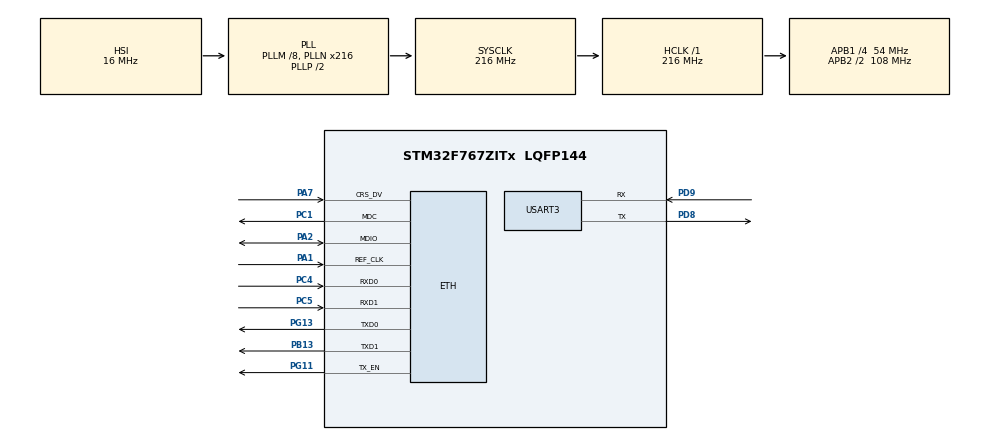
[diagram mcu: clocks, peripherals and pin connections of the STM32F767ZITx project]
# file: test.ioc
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CORTEX_M7.AccessPermission-Cortex_Memory_Protection_Unit_Region1_Settings=MPU_REGION_FULL_ACCESS
CORTEX_M7.AccessPermission-Cortex_Memory_Protection_Unit_Region2_Settings=MPU_REGION_FULL_ACCESS
CORTEX_M7.BaseAddress-Cortex_Memory_Protection_Unit_Region0_Settings=0x70000000
CORTEX_M7.BaseAddress-Cortex_Memory_Protection_Unit_Region1_Settings=0x70000000
CORTEX_M7.BaseAddress-Cortex_Memory_Protection_Unit_Region2_Settings=0x70000000
CORTEX_M7.CPU_DCache=Enabled
CORTEX_M7.CPU_ICache=Enabled
CORTEX_M7.DisableExec-Cortex_Memory_Protection_Unit_Region0_Settings=MPU_INSTRUCTION_ACCESS_DISABLE
CORTEX_M7.DisableExec-Cortex_Memory_Protection_Unit_Region1_Settings=MPU_INSTRUCTION_ACCESS_DISABLE
CORTEX_M7.Enable-Cortex_Memory_Protection_Unit_Region0_Settings=MPU_REGION_ENABLE
CORTEX_M7.Enable-Cortex_Memory_Protection_Unit_Region1_Settings=MPU_REGION_ENABLE
CORTEX_M7.Enable-Cortex_Memory_Protection_Unit_Region2_Settings=MPU_REGION_ENABLE
CORTEX_M7.IsBufferable-Cortex_Memory_Protection_Unit_Region1_Settings=MPU_ACCESS_BUFFERABLE
CORTEX_M7.IsBufferable-Cortex_Memory_Protection_Unit_Region2_Settings=MPU_ACCESS_BUFFERABLE
CORTEX_M7.IsCacheable-Cortex_Memory_Protection_Unit_Region1_Settings=MPU_ACCESS_CACHEABLE
CORTEX_M7.IsCacheable-Cortex_Memory_Protection_Unit_Region2_Settings=MPU_ACCESS_CACHEABLE
CORTEX_M7.MPU_Control=MPU_PRIVILEGED_DEFAULT
CORTEX_M7.PREFETCH_ENABLE=1
CORTEX_M7.Size-Cortex_Memory_Protection_Unit_Region0_Settings=MPU_REGION_SIZE_512MB
CORTEX_M7.Size-Cortex_Memory_Protection_Unit_Region1_Settings=MPU_REGION_SIZE_16MB
CORTEX_M7.Size-Cortex_Memory_Protection_Unit_Region2_Settings=MPU_REGION_SIZE_1MB
ETH.MediaInterface=ETH_MEDIA_INTERFACE_RMII
ETH.PhyAddress=0
ETH.RxMode=ETH_RXINTERRUPT_MODE
FREERTOS.Tasks01=defaultTask,24,128,StartDefaultTask,Default,NULL,Dynamic,NULL,NULL;TaskUART01,24,128,StartTask02,Default,NULL,Dynamic,NULL,NULL
FREERTOS.configUSE_NEWLIB_REENTRANT=1
LWIP.GATEWAY_ADDRESS=192.168.000.001
LWIP.IP_ADDRESS=192.168.000.123
LWIP.LWIP_DHCP=0
LWIP.LWIP_HTTPD=1
LWIP.MEM_SIZE=10*1024
LWIP.NETMASK_ADDRESS=255.255.255.000
LWIP.Version=v2.1.2_Cube
Mcu.Family=STM32F7
Mcu.Name=STM32F767ZITx
Mcu.Package=LQFP144
NVIC.ETH_IRQn=true\:5\:0\:false\:false\:true\:true\:false\:true\:true
NVIC.PriorityGroup=NVIC_PRIORITYGROUP_4
PA1.Mode=RMII
PA1.Signal=ETH_REF_CLK
PA2.Mode=RMII
PA2.Signal=ETH_MDIO
PA7.Mode=RMII
PA7.Signal=ETH_CRS_DV
PB13.Mode=RMII
PB13.Signal=ETH_TXD1
PC1.Mode=RMII
PC1.Signal=ETH_MDC
PC4.Mode=RMII
PC4.Signal=ETH_RXD0
PC5.Mode=RMII
PC5.Signal=ETH_RXD1
PD8.Mode=Asynchronous
PD8.Signal=USART3_TX
PD9.Mode=Asynchronous
PD9.Signal=USART3_RX
PG11.Mode=RMII
PG11.Signal=ETH_TX_EN
PG13.Mode=RMII
PG13.Signal=ETH_TXD0
PH0/OSC_IN.Mode=HSE-External-Oscillator
PH0/OSC_IN.Signal=RCC_OSC_IN
PH1/OSC_OUT.Mode=HSE-External-Oscillator
PH1/OSC_OUT.Signal=RCC_OSC_OUT
ProjectManager.HeapSize=0x200
ProjectManager.StackSize=0x400
ProjectManager.TargetToolchain=STM32CubeIDE
RCC.AHBFreq_Value=216000000
RCC.APB1CLKDivider=RCC_HCLK_DIV4
RCC.APB1Freq_Value=54000000
RCC.APB1TimFreq_Value=108000000
RCC.APB2CLKDivider=RCC_HCLK_DIV2
RCC.APB2Freq_Value=108000000
RCC.APB2TimFreq_Value=216000000
RCC.CortexFreq_Value=216000000
RCC.HCLKFreq_Value=216000000
RCC.HSE_VALUE=25000000
RCC.HSI_VALUE=16000000
RCC.LSE_VALUE=32768
RCC.PLLM=8
RCC.PLLN=216
RCC.SYSCLKFreq_VALUE=216000000
RCC.SYSCLKSource=RCC_SYSCLKSOURCE_PLLCLK
RCC.USBFreq_Value=216000000
RCC.VCOOutputFreq_Value=432000000
USART3.VirtualMode-Asynchronous=VM_ASYNC
VP_FREERTOS_VS_CMSIS_V2.Mode=CMSIS_V2
VP_LWIP_VS_Enabled.Mode=Enabled
board=custom

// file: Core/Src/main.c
/* USER CODE BEGIN Header */
/**
  ******************************************************************************
  * @file           : main.c
  * @brief          : Main program body
  ******************************************************************************
  * @attention
  *
  * Copyright (c) 2024 STMicroelectronics.
  * All rights reserved.
  *
  * This software is licensed under terms that can be found in the LICENSE file
  * in the root directory of this software component.
  * If no LICENSE file comes with this software, it is provided AS-IS.
  *
  ******************************************************************************
  */
/* USER CODE END Header */
#include "main.h"
#include "cmsis_os.h"
#include "lwip.h"

/* USER CODE BEGIN Includes */
#include "httpserver.h"
/* USER CODE END Includes */

UART_HandleTypeDef huart3;

/* Definitions for defaultTask */
osThreadId_t defaultTaskHandle;
const osThreadAttr_t defaultTask_attributes = {
  .name = "defaultTask",
  .stack_size = 128 * 4,
  .priority = (osPriority_t) osPriorityNormal,
};
/* Definitions for TaskUART01 */
osThreadId_t TaskUART01Handle;
const osThreadAttr_t TaskUART01_attributes = {
  .name = "TaskUART01",
  .stack_size = 128 * 4,
  .priority = (osPriority_t) osPriorityNormal,
};

void SystemClock_Config(void);
static void MPU_Config(void);
static void MX_GPIO_Init(void);
static void MX_USART3_UART_Init(void);
void StartDefaultTask(void *argument);
void StartTask02(void *argument);

int main(void)
{

  /* MPU Configuration--------------------------------------------------------*/
  MPU_Config();

  /* Enable I-Cache---------------------------------------------------------*/
  SCB_EnableICache();

  /* Enable D-Cache---------------------------------------------------------*/
  SCB_EnableDCache();

  /* MCU Configuration--------------------------------------------------------*/

  /* Reset of all peripherals, Initializes the Flash interface and the Systick. */
  HAL_Init();

  /* Configure the system clock */
  SystemClock_Config();

  /* Initialize all configured peripherals */
  MX_GPIO_Init();
  MX_USART3_UART_Init();

  /* Init scheduler */
  osKernelInitialize();

  /* Create the thread(s) */
  /* creation of defaultTask */
  defaultTaskHandle = osThreadNew(StartDefaultTask, NULL, &defaultTask_attributes);

  /* creation of TaskUART01 */
  TaskUART01Handle = osThreadNew(StartTask02, NULL, &TaskUART01_attributes);

  /* Start scheduler */
  osKernelStart();

  /* We should never get here as control is now taken by the scheduler */
  /* Infinite loop */
  while (1)
  {

  }
}

void SystemClock_Config(void)
{
  RCC_OscInitTypeDef RCC_OscInitStruct = {0};
  RCC_ClkInitTypeDef RCC_ClkInitStruct = {0};

  /** Configure the main internal regulator output voltage
  */
  __HAL_RCC_PWR_CLK_ENABLE();
  __HAL_PWR_VOLTAGESCALING_CONFIG(PWR_REGULATOR_VOLTAGE_SCALE1);

  /** Initializes the RCC Oscillators according to the specified parameters
  * in the RCC_OscInitTypeDef structure.
  */
  RCC_OscInitStruct.OscillatorType = RCC_OSCILLATORTYPE_HSI;
  RCC_OscInitStruct.HSIState = RCC_HSI_ON;
  RCC_OscInitStruct.HSICalibrationValue = RCC_HSICALIBRATION_DEFAULT;
  RCC_OscInitStruct.PLL.PLLState = RCC_PLL_ON;
  RCC_OscInitStruct.PLL.PLLSource = RCC_PLLSOURCE_HSI;
  RCC_OscInitStruct.PLL.PLLM = 8;
  RCC_OscInitStruct.PLL.PLLN = 216;
  RCC_OscInitStruct.PLL.PLLP = RCC_PLLP_DIV2;
  RCC_OscInitStruct.PLL.PLLQ = 2;
  RCC_OscInitStruct.PLL.PLLR = 2;
  if (HAL_RCC_OscConfig(&RCC_OscInitStruct) != HAL_OK)
  {
    Error_Handler();
  }

  /** Activate the Over-Drive mode
  */
  if (HAL_PWREx_EnableOverDrive() != HAL_OK)
  {
    Error_Handler();
  }

  /** Initializes the CPU, AHB and APB buses clocks
  */
  RCC_ClkInitStruct.ClockType = RCC_CLOCKTYPE_HCLK|RCC_CLOCKTYPE_SYSCLK
                              |RCC_CLOCKTYPE_PCLK1|RCC_CLOCKTYPE_PCLK2;
  RCC_ClkInitStruct.SYSCLKSource = RCC_SYSCLKSOURCE_PLLCLK;
  RCC_ClkInitStruct.AHBCLKDivider = RCC_SYSCLK_DIV1;
  RCC_ClkInitStruct.APB1CLKDivider = RCC_HCLK_DIV4;
  RCC_ClkInitStruct.APB2CLKDivider = RCC_HCLK_DIV2;

  if (HAL_RCC_ClockConfig(&RCC_ClkInitStruct, FLASH_LATENCY_7) != HAL_OK)
  {
    Error_Handler();
  }
}

static void MX_USART3_UART_Init(void)
{

  huart3.Instance = USART3;
  huart3.Init.BaudRate = 115200;
  huart3.Init.WordLength = UART_WORDLENGTH_8B;
  huart3.Init.StopBits = UART_STOPBITS_1;
  huart3.Init.Parity = UART_PARITY_NONE;
  huart3.Init.Mode = UART_MODE_TX_RX;
  huart3.Init.HwFlowCtl = UART_HWCONTROL_NONE;
  huart3.Init.OverSampling = UART_OVERSAMPLING_16;
  huart3.Init.OneBitSampling = UART_ONE_BIT_SAMPLE_DISABLE;
  huart3.AdvancedInit.AdvFeatureInit = UART_ADVFEATURE_NO_INIT;
  if (HAL_UART_Init(&huart3) != HAL_OK)
  {
    Error_Handler();
  }

}

static void MX_GPIO_Init(void)
{

  /* GPIO Ports Clock Enable */
  __HAL_RCC_GPIOH_CLK_ENABLE();
  __HAL_RCC_GPIOC_CLK_ENABLE();
  __HAL_RCC_GPIOA_CLK_ENABLE();
  __HAL_RCC_GPIOB_CLK_ENABLE();
  __HAL_RCC_GPIOD_CLK_ENABLE();
  __HAL_RCC_GPIOG_CLK_ENABLE();

}

void StartDefaultTask(void *argument)
{
  /* init code for LWIP */
  MX_LWIP_Init();
  /* USER CODE BEGIN 5 */
  http_server_init();
  /* Infinite loop */
  for(;;)
  {
    osDelay(1);
  }
  /* USER CODE END 5 */
}

void StartTask02(void *argument)
{
  /* USER CODE BEGIN StartTask02 */
  /* Infinite loop */
  for(;;)
  {
	  //HAL_UART_Transmit(&huart3, txt, sizeof(txt),Tmeout );
    osDelay(5000);
  }
  /* USER CODE END StartTask02 */
}

/* MPU Configuration */

void MPU_Config(void)
{
  MPU_Region_InitTypeDef MPU_InitStruct = {0};

  /* Disables the MPU */
  HAL_MPU_Disable();

  /** Initializes and configures the Region and the memory to be protected
  */
  MPU_InitStruct.Enable = MPU_REGION_ENABLE;
  MPU_InitStruct.Number = MPU_REGION_NUMBER0;
  MPU_InitStruct.BaseAddress = 0x70000000;
  MPU_InitStruct.Size = MPU_REGION_SIZE_512MB;
  MPU_InitStruct.SubRegionDisable = 0x0;
  MPU_InitStruct.TypeExtField = MPU_TEX_LEVEL0;
  MPU_InitStruct.AccessPermission = MPU_REGION_NO_ACCESS;
  MPU_InitStruct.DisableExec = MPU_INSTRUCTION_ACCESS_DISABLE;
  MPU_InitStruct.IsShareable = MPU_ACCESS_NOT_SHAREABLE;
  MPU_InitStruct.IsCacheable = MPU_ACCESS_NOT_CACHEABLE;
  MPU_InitStruct.IsBufferable = MPU_ACCESS_NOT_BUFFERABLE;

  HAL_MPU_ConfigRegion(&MPU_InitStruct);

  /** Initializes and configures the Region and the memory to be protected
  */
  MPU_InitStruct.Number = MPU_REGION_NUMBER1;
  MPU_InitStruct.Size = MPU_REGION_SIZE_16MB;
  MPU_InitStruct.AccessPermission = MPU_REGION_FULL_ACCESS;
  MPU_InitStruct.IsCacheable = MPU_ACCESS_CACHEABLE;
  MPU_InitStruct.IsBufferable = MPU_ACCESS_BUFFERABLE;

  HAL_MPU_ConfigRegion(&MPU_InitStruct);

  /** Initializes and configures the Region and the memory to be protected
  */
  MPU_InitStruct.Number = MPU_REGION_NUMBER2;
  MPU_InitStruct.Size = MPU_REGION_SIZE_1MB;
  MPU_InitStruct.DisableExec = MPU_INSTRUCTION_ACCESS_ENABLE;

  HAL_MPU_ConfigRegion(&MPU_InitStruct);
  /* Enables the MPU */
  HAL_MPU_Enable(MPU_PRIVILEGED_DEFAULT);

}

void Error_Handler(void)
{
  __disable_irq();
  while (1)
  {
  }
}
